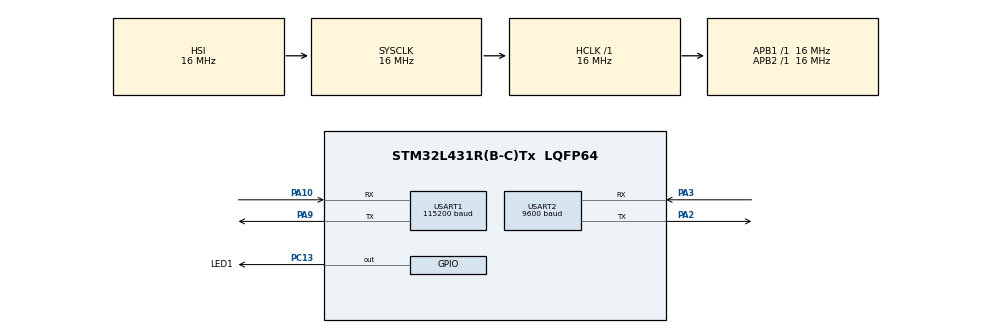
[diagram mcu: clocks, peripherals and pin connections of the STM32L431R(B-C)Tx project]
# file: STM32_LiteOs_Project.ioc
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Mcu.Family=STM32L4
Mcu.Name=STM32L431R(B-C)Tx
Mcu.Package=LQFP64
NVIC.PriorityGroup=NVIC_PRIORITYGROUP_4
NVIC.RCC_IRQn=true\:0\:0\:false\:false\:true\:true\:false
NVIC.USART1_IRQn=true\:0\:0\:false\:false\:true\:true\:true
NVIC.USART2_IRQn=true\:0\:0\:false\:false\:true\:true\:true
PA10.Mode=Asynchronous
PA10.Signal=USART1_RX
PA2.Mode=Asynchronous
PA2.Signal=USART2_TX
PA3.Mode=Asynchronous
PA3.Signal=USART2_RX
PA9.Mode=Asynchronous
PA9.Signal=USART1_TX
PC13.GPIO_Label=LED1
PC13.Signal=GPIO_Output
ProjectManager.HeapSize=0x200
ProjectManager.StackSize=0x400
ProjectManager.TargetToolchain=MDK-ARM V5
RCC.AHBFreq_Value=16000000
RCC.APB1Freq_Value=16000000
RCC.APB1TimFreq_Value=16000000
RCC.APB2Freq_Value=16000000
RCC.APB2TimFreq_Value=16000000
RCC.CortexFreq_Value=16000000
RCC.HCLKFreq_Value=16000000
RCC.HSE_VALUE=8000000
RCC.HSI48_VALUE=48000000
RCC.HSI_VALUE=16000000
RCC.LSE_VALUE=32768
RCC.MSI_VALUE=4000000
RCC.SYSCLKFreq_VALUE=16000000
RCC.SYSCLKSource=RCC_SYSCLKSOURCE_HSI
RCC.VCOOutputFreq_Value=32000000
USART1.BaudRate=115200
USART1.VirtualMode-Asynchronous=VM_ASYNC
USART2.BaudRate=9600
USART2.VirtualMode-Asynchronous=VM_ASYNC
board=custom

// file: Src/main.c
/* USER CODE BEGIN Header */
/**
  ******************************************************************************
  * @file           : main.c
  * @brief          : Main program body
  ******************************************************************************
  * @attention
  *
  * <h2><center>&copy; Copyright (c) 2019 STMicroelectronics.
  * All rights reserved.</center></h2>
  *
  * This software component is licensed by ST under BSD 3-Clause license,
  * the "License"; You may not use this file except in compliance with the
  * License. You may obtain a copy of the License at:
  *                        opensource.org/licenses/BSD-3-Clause
  *
  ******************************************************************************
  */
/* USER CODE END Header */

#include "main.h"
#include "usart.h"
#include "gpio.h"

/* USER CODE BEGIN Includes */
#include "los_base.h"
#include "los_inspect_entry.h"

/* USER CODE END Includes */

void SystemClock_Config(void);
/* USER CODE BEGIN PFP */
UINT32 Example_Entry(VOID);
/* USER CODE END PFP */

int main(void)
{

  /* MCU Configuration--------------------------------------------------------*/

  /* Reset of all peripherals, Initializes the Flash interface and the Systick. */
  HAL_Init();

  /* Configure the system clock */
  SystemClock_Config();

  /* Initialize all configured peripherals */
  MX_GPIO_Init();
  MX_USART2_UART_Init();
  MX_USART1_UART_Init();
  /* USER CODE BEGIN 2 */

  if(LOS_OK != LOS_KernelInit())
  {
	 return LOS_NOK;
  }

  Example_Entry();
  LOS_Start();

  /* USER CODE END 2 */

  /* Infinite loop */
  /* USER CODE BEGIN WHILE */
  while (1)
  {

//	if(LOS_OK != LOS_KernelInit())
//	{
//		return LOS_NOK;
//	}
//
//	LOS_Inspect_Entry();
//	LOS_Start();
//
//	HAL_GPIO_TogglePin(LED1_GPIO_Port, LED1_Pin);
//	printf(" ***************** \r\n");

    /* USER CODE END WHILE */

  }
}

void SystemClock_Config(void)
{
  RCC_OscInitTypeDef RCC_OscInitStruct = {0};
  RCC_ClkInitTypeDef RCC_ClkInitStruct = {0};
  RCC_PeriphCLKInitTypeDef PeriphClkInit = {0};

  /** Initializes the CPU, AHB and APB busses clocks
  */
  RCC_OscInitStruct.OscillatorType = RCC_OSCILLATORTYPE_HSI;
  RCC_OscInitStruct.HSIState = RCC_HSI_ON;
  RCC_OscInitStruct.HSICalibrationValue = RCC_HSICALIBRATION_DEFAULT;
  RCC_OscInitStruct.PLL.PLLState = RCC_PLL_NONE;
  if (HAL_RCC_OscConfig(&RCC_OscInitStruct) != HAL_OK)
  {
    Error_Handler();
  }
  /** Initializes the CPU, AHB and APB busses clocks
  */
  RCC_ClkInitStruct.ClockType = RCC_CLOCKTYPE_HCLK|RCC_CLOCKTYPE_SYSCLK
                              |RCC_CLOCKTYPE_PCLK1|RCC_CLOCKTYPE_PCLK2;
  RCC_ClkInitStruct.SYSCLKSource = RCC_SYSCLKSOURCE_HSI;
  RCC_ClkInitStruct.AHBCLKDivider = RCC_SYSCLK_DIV1;
  RCC_ClkInitStruct.APB1CLKDivider = RCC_HCLK_DIV1;
  RCC_ClkInitStruct.APB2CLKDivider = RCC_HCLK_DIV1;

  if (HAL_RCC_ClockConfig(&RCC_ClkInitStruct, FLASH_LATENCY_0) != HAL_OK)
  {
    Error_Handler();
  }
  PeriphClkInit.PeriphClockSelection = RCC_PERIPHCLK_USART1|RCC_PERIPHCLK_USART2;
  PeriphClkInit.Usart1ClockSelection = RCC_USART1CLKSOURCE_PCLK2;
  PeriphClkInit.Usart2ClockSelection = RCC_USART2CLKSOURCE_PCLK1;
  if (HAL_RCCEx_PeriphCLKConfig(&PeriphClkInit) != HAL_OK)
  {
    Error_Handler();
  }
  /** Configure the main internal regulator output voltage
  */
  if (HAL_PWREx_ControlVoltageScaling(PWR_REGULATOR_VOLTAGE_SCALE1) != HAL_OK)
  {
    Error_Handler();
  }
}

void Error_Handler(void)
{
}

/************************ (C) COPYRIGHT STMicroelectronics *****END OF FILE****/
